# NSS_0_CFG_CPPIDMA0_CONFIG register map
Vendor: Texas Instruments
Peripheral module from a debugger description file (folder 66AK2G0x_66AK2G1x).
Registers are 32-bit, access per field, reset 0x0 unless marked. A register's access mark holds for its fields unless they carry their own. Offsets are as the file gives them; lines under a group give offsets from that group; [hi:lo] are bit positions; {n}, {i} and the like mark numbered series; 'fields as' and 'values as' point back to an identical list; <NAME> marks a mode.

## NSS_0_CFG_CPPIDMA0_CONFIG
0x00 CDMA_REVISION_REG ro reset 0x4E5AA900
  [31:0] REV — TI internal data. Identifies revision of peripheral.
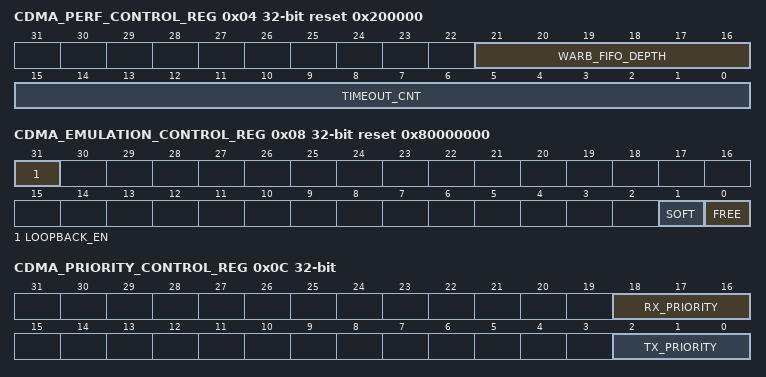
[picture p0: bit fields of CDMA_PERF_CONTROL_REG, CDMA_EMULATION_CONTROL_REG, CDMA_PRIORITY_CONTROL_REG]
0x04 CDMA_PERF_CONTROL_REG reset 0x200000
  [21:16] WARB_FIFO_DEPTH rw — This field sets the depth of the write arbitration FIFO which stores write transaction information between the command arbiter and write data arbiters in the Bus Interface Unit. This value can be set to a range of 1 to 32. Setting this field to smaller values will cause prevent the CDMAHP from having an excess of write transactions outstanding whose data is still waiting to be transferred. System performance can suffer if write commands are allowed to be issued long before the corresponding write data will be transferred. This field allows the command count to be optimized based on system dynamics.
  [15:0] TIMEOUT_CNT rw — This field sets the timeout duration in clock cycles. This field controls the minimum amount of time that an Rx channel will be required to wait when it encounters a buffer starvation condition and the Rx error handling bit is set to 1 (packet is to be preserved - no discard). If the Rx error handling bit in the flow table is cleared, this field will have no effect on the Rx operation. When this field is set to 0, the Rx engine will not force an Rx channel to wait after encountering a starvation event (the feature is disabled). When this field is set to a value other than 0, the Rx engine will force any channel whose associated flow had the Rx error handling bit asserted and which encounters starvation to wait for at least the specified # of clock cycles before coming into context again to retry the access to the QM. This is intended to control potentially debilitating effects on the QM performance that can becaused by the CDMAHP modules continually polling the QM. The exact # of clock cycles between QM access attempts is not important and will not be exact. The only guarantee is that the # of cycles waited will be at least as large as the TIMEOUT_CNT.
0x08 CDMA_EMULATION_CONTROL_REG reset 0x80000000
  [31] LOOPBACK_EN rw — Streaming Interface loopback enable
  [1] SOFT rw
  [0] FREE rw
{0xA+4i} CDMA_QM_BASE_ADDRESS_REG_{i} rw (i=0..2)
  [31:0] QMI_BASE — Provides a programmable pointer to the base address of the queues region for this instance of the Queue Manager
0x0C CDMA_PRIORITY_CONTROL_REG
  [18:16] RX_PRIORITY rw — Rx priority: This field contains the 3-bit value which will be output on the mem_cpriority and mem_cepriority outputs during all Rx transactions.
  [2:0] TX_PRIORITY rw — Tx priority: This field contains the 3-bit value which will be output on the mem_cpriority and mem_cepriority outputs during all Tx transactions.
